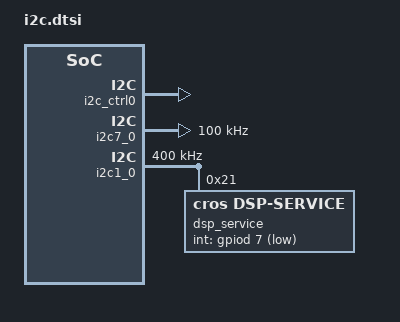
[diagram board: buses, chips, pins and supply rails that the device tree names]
/* Copyright 2025 The ChromiumOS Authors
 * Use of this source code is governed by a BSD-style license that can be
 * found in the LICENSE file.
 */

&i2c_ctrl0 {
	status = "okay";
};

&i2c7_0 {
	clock-frequency = <I2C_BITRATE_STANDARD>;
};

&i2c1_0 {
        status = "okay";
        label = "I2C_SENSOR";
        clock-frequency = <I2C_BITRATE_FAST>;
        dsp_service: dsp-service@21 {
                compatible = "cros,dsp-service";
                reg = <0x21>;
                int-gpios = <&gpiod 7 (GPIO_OPEN_DRAIN | GPIO_ACTIVE_LOW)>;
        };
};
